AUTOSAR XML (schema 00050)
package /Pkg_ErrorMgrSat_1_0_B/ComponentTypes
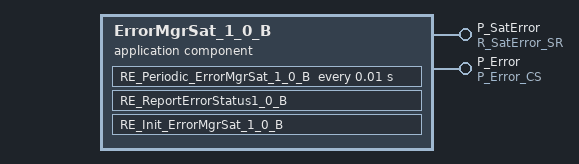
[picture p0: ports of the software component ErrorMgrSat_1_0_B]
  application sw component type ErrorMgrSat_1_0_B
    provide port P_SatError: provided-interface=R_SatError_SR
      provided-com-specs:
        data-element=Data_ErrorMgr_ErrorCommPack_1_0_B, init-value=constant-reference=init_Data_ErrorMgr_ErrorCommPack_1_0_B
        data-element=Data_ErrorMgr_ErrorCommPack_2_0_B, init-value=fields=[RunningCounter:0, Checksum:0, Error:144 x 0, Data:144 x fields=AdditionalData:[0, 0, 0, 0]]
        data-element=Data_ErrorMgr_ErrorCommPack_2_1_B, init-value=fields=[RunningCounter:0, Checksum:0, Error:548 x 0, Data:548 x fields=AdditionalData:[0, 0, 0, 0]]
        data-element=Data_ErrorMgr_ErrorCommPack_QNX_B, init-value=fields=[RunningCounter:0, Checksum:0, Error:8 x 0, Data:8 x fields=AdditionalData:[0, 0, 0, 0]]
        Data_ErrorMgr_ErrorCommPack_2_0_B
        Data_ErrorMgr_ErrorCommPack_2_1_B
        Data_ErrorMgr_ErrorCommPack_QNX_B
    provide port P_Error: server-com-spec{operation=ReportErrorStatus1_0_B, queue-length=1}, provided-interface=P_Error_CS
    behavior ErrorMgrSat_1_0_B_InternalBehavior: handle-termination-and-restart=NO-SUPPORT
      timing event TMT_RE_Periodic_ErrorMgrSat_1_0_B: start-on-event=RE_Periodic_ErrorMgrSat_1_0_B, period=0.01
      init event InitEvent: start-on-event=RE_Init_ErrorMgrSat_1_0_B
      operation invoked event OIT_RE_ReportErrorStatus1_0_B_P_Error_ReportErrorStatus1_0_B: start-on-event=RE_ReportErrorStatus1_0_B, operation=P_Error.ReportErrorStatus1_0_B
      port-api-options:
        enable-take-address=false, indirect-api=false, port=P_Error
        enable-take-address=false, indirect-api=false, port=P_SatError
      runnable RE_Periodic_ErrorMgrSat_1_0_B  # Periodic Runnable of Satellite
        data-send-points:
          access SEND_P_SatError_Data_ErrorMgr_ErrorCommPack_1_0_B: accessed-variable=P_SatError.Data_ErrorMgr_ErrorCommPack_1_0_B
      runnable RE_ReportErrorStatus1_0_B: can-be-invoked-concurrently=true  # Server Runnable for handling the error reporting
      runnable RE_Init_ErrorMgrSat_1_0_B  # Init Runnable
  swc implementation ErrorMgrSat_1_0_B_Implementation: programming-language=C, vendor-id=0, behavior=ErrorMgrSat_1_0_B_InternalBehavior
    code-descriptors:
      code Default: artifact-descriptors=autosar-engineering-object=category=SWSRC
